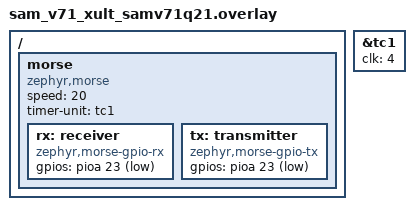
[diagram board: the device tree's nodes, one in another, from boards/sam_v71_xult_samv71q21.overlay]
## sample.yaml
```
sample:
  name: Morse Code Sample
tests:
  sample.subsys.morse.morse_code:
    tags:
      - drivers
      - morse_code
    harness: grove
    depends_on: counter
    filter: dt_compat_enabled("zephyr,morse")
    platform_allow:
      - nrf52840dk/nrf52840
      - nucleo_f767zi
      - nucleo_g474re
      - sam_v71_xult/samv71q21
```

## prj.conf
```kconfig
CONFIG_LOG=y

CONFIG_COUNTER=y
CONFIG_MORSE=y

CONFIG_SHELL=y
CONFIG_MORSE_SHELL=y
```

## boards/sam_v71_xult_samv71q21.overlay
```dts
/*
 * Copyright (c) 2024-2025 Freedom Veiculos Eletricos
 * Copyright (c) 2024-2025 OS Systems
 *
 * SPDX-License-Identifier: Apache-2.0
 */

/ {
	morse: morse {
		compatible = "zephyr,morse";

		speed = <20>;
		timer-unit = <&tc1>;

		rx: receiver {
			compatible = "zephyr,morse-gpio-rx";

			gpios = <&pioa 23 GPIO_ACTIVE_LOW>;
		};

		tx: transmitter {
			compatible = "zephyr,morse-gpio-tx";

			gpios = <&pioa 23 GPIO_ACTIVE_LOW>;
		};
	};
};

&tc1 {
	clk = <4>;
	status = "okay";
};
```

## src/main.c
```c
/*
 * Copyright (c) 2024 Freedom Veiculos Eletricos
 * Copyright (c) 2024 OS Systems
 *
 * SPDX-License-Identifier: Apache-2.0
 */

#include <zephyr/kernel.h>
#include <zephyr/device.h>

#include <zephyr/morse/morse.h>

#include <zephyr/logging/log.h>
LOG_MODULE_REGISTER(app, CONFIG_MORSE_LOG_LEVEL);

/**
 * @file Send data using morse code.
 */

const uint8_t data[] = "paris";

void morse_cb_handler(void *ctx, int status)
{
	LOG_INF("Status: %d", status);
}

int main(void)
{
	const struct device *const morse = DEVICE_DT_GET(DT_NODELABEL(morse));

	if (!device_is_ready(morse)) {
		return 0;
	}

	morse_manage_callbacks(morse, morse_cb_handler, NULL, NULL);
	morse_send(morse, data, strlen(data));

	return 0;
}
```
